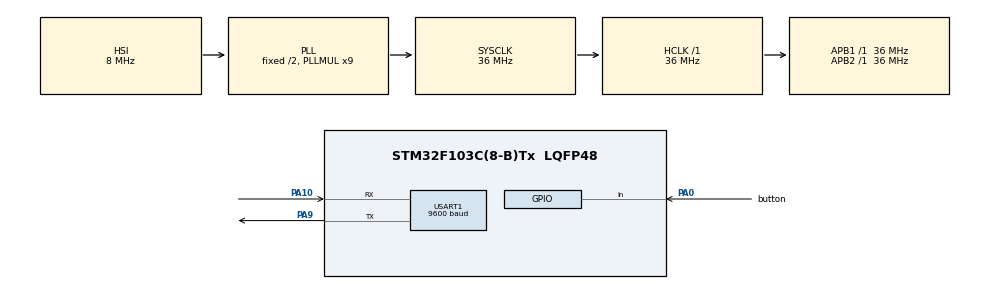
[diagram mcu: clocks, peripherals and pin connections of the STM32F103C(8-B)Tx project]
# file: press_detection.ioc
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Mcu.Family=STM32F1
Mcu.Name=STM32F103C(8-B)Tx
Mcu.Package=LQFP48
NVIC.PriorityGroup=NVIC_PRIORITYGROUP_4
PA0-WKUP.GPIO_Label=button
PA0-WKUP.GPIO_PuPd=GPIO_PULLUP
PA0-WKUP.Signal=GPIO_Input
PA10.Mode=Asynchronous
PA10.Signal=USART1_RX
PA9.Mode=Asynchronous
PA9.Signal=USART1_TX
ProjectManager.HeapSize=0x200
ProjectManager.StackSize=0x400
ProjectManager.TargetToolchain=MDK-ARM V5.32
RCC.AHBFreq_Value=36000000
RCC.APB1Freq_Value=36000000
RCC.APB1TimFreq_Value=36000000
RCC.APB2Freq_Value=36000000
RCC.APB2TimFreq_Value=36000000
RCC.HCLKFreq_Value=36000000
RCC.PLLMUL=RCC_PLL_MUL9
RCC.SYSCLKFreq_VALUE=36000000
RCC.SYSCLKSource=RCC_SYSCLKSOURCE_PLLCLK
RCC.USBFreq_Value=36000000
USART1.BaudRate=9600
USART1.VirtualMode=VM_ASYNC
VP_SYS_VS_ND.Mode=No_Debug
board=custom

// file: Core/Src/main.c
/* USER CODE BEGIN Header */
/**
  ******************************************************************************
  * @file           : main.c
  * @brief          : Main program body
  ******************************************************************************
  * @attention
  *
  * Copyright (c) 2026 STMicroelectronics.
  * All rights reserved.
  *
  * This software is licensed under terms that can be found in the LICENSE file
  * in the root directory of this software component.
  * If no LICENSE file comes with this software, it is provided AS-IS.
  *
  ******************************************************************************
  */
/* USER CODE END Header */
#include "main.h"

/* USER CODE BEGIN Includes */
#include <string.h>
#include <stdio.h>
/* USER CODE END Includes */

UART_HandleTypeDef huart1;

/* USER CODE BEGIN PV */
uint8_t last_state = 0;
uint16_t time_press = 0;
uint16_t time_release = 0;
uint8_t numbers = 0;
/* USER CODE END PV */

void SystemClock_Config(void);
static void MX_GPIO_Init(void);
static void MX_USART1_UART_Init(void);

/* USER CODE BEGIN 0 */
void uart_print(const char *s) {
	HAL_UART_Transmit(&huart1, (uint8_t *)s, strlen(s), 100);
}
/* USER CODE END 0 */

int main(void)
{

  /* MCU Configuration--------------------------------------------------------*/

  /* Reset of all peripherals, Initializes the Flash interface and the Systick. */
  HAL_Init();

  /* Configure the system clock */
  SystemClock_Config();

  /* Initialize all configured peripherals */
  MX_GPIO_Init();
  MX_USART1_UART_Init();
  /* USER CODE BEGIN 2 */
	uart_print("hello 0038\r\n");
  /* USER CODE END 2 */

  /* Infinite loop */
  while (1)
  {

    /* USER CODE BEGIN 3 */
		uint8_t now_state = (HAL_GPIO_ReadPin(button_GPIO_Port, button_Pin) == GPIO_PIN_RESET);

		if (now_state == 1 && last_state == 0) {
			time_press = HAL_GetTick();
		} else if (now_state == 0 && last_state == 1) {
			time_release = HAL_GetTick();
			uint32_t times = time_release - time_press;

			if (times >= 800) {
				uart_print("Long Press\r\n");
				numbers = 0;
			} else {
				numbers++;
			}
		}
		last_state = now_state;

		if (numbers > 0 && now_state == 0 && (HAL_GetTick() - time_release) >= 300) {
			if (numbers == 1) {
				uart_print("Click\r\n");
			} else {
				uart_print("Double Click\r\n");
			}
			numbers = 0;
		}
  }
  /* USER CODE END 3 */
}

void SystemClock_Config(void)
{
  RCC_OscInitTypeDef RCC_OscInitStruct = {0};
  RCC_ClkInitTypeDef RCC_ClkInitStruct = {0};

  /** Initializes the RCC Oscillators according to the specified parameters
  * in the RCC_OscInitTypeDef structure.
  */
  RCC_OscInitStruct.OscillatorType = RCC_OSCILLATORTYPE_HSI;
  RCC_OscInitStruct.HSIState = RCC_HSI_ON;
  RCC_OscInitStruct.HSICalibrationValue = RCC_HSICALIBRATION_DEFAULT;
  RCC_OscInitStruct.PLL.PLLState = RCC_PLL_ON;
  RCC_OscInitStruct.PLL.PLLSource = RCC_PLLSOURCE_HSI_DIV2;
  RCC_OscInitStruct.PLL.PLLMUL = RCC_PLL_MUL9;
  if (HAL_RCC_OscConfig(&RCC_OscInitStruct) != HAL_OK)
  {
    Error_Handler();
  }

  /** Initializes the CPU, AHB and APB buses clocks
  */
  RCC_ClkInitStruct.ClockType = RCC_CLOCKTYPE_HCLK|RCC_CLOCKTYPE_SYSCLK
                              |RCC_CLOCKTYPE_PCLK1|RCC_CLOCKTYPE_PCLK2;
  RCC_ClkInitStruct.SYSCLKSource = RCC_SYSCLKSOURCE_PLLCLK;
  RCC_ClkInitStruct.AHBCLKDivider = RCC_SYSCLK_DIV1;
  RCC_ClkInitStruct.APB1CLKDivider = RCC_HCLK_DIV1;
  RCC_ClkInitStruct.APB2CLKDivider = RCC_HCLK_DIV1;

  if (HAL_RCC_ClockConfig(&RCC_ClkInitStruct, FLASH_LATENCY_1) != HAL_OK)
  {
    Error_Handler();
  }
}

static void MX_USART1_UART_Init(void)
{

  huart1.Instance = USART1;
  huart1.Init.BaudRate = 9600;
  huart1.Init.WordLength = UART_WORDLENGTH_8B;
  huart1.Init.StopBits = UART_STOPBITS_1;
  huart1.Init.Parity = UART_PARITY_NONE;
  huart1.Init.Mode = UART_MODE_TX_RX;
  huart1.Init.HwFlowCtl = UART_HWCONTROL_NONE;
  huart1.Init.OverSampling = UART_OVERSAMPLING_16;
  if (HAL_UART_Init(&huart1) != HAL_OK)
  {
    Error_Handler();
  }

}

static void MX_GPIO_Init(void)
{
  GPIO_InitTypeDef GPIO_InitStruct = {0};

  /* GPIO Ports Clock Enable */
  __HAL_RCC_GPIOA_CLK_ENABLE();

  /*Configure GPIO pin : button_Pin */
  GPIO_InitStruct.Pin = button_Pin;
  GPIO_InitStruct.Mode = GPIO_MODE_INPUT;
  GPIO_InitStruct.Pull = GPIO_PULLUP;
  HAL_GPIO_Init(button_GPIO_Port, &GPIO_InitStruct);

}

void Error_Handler(void)
{
  __disable_irq();
  while (1)
  {
  }
}
